# PIC32CX5112MTSH128 device description
Architecture: CORTEX-M4; Family: PIC32CXMT; Series: PIC32CXMTSH
Registers are 32-bit, read-write, no defined reset value unless marked. A register's access mark holds for its fields unless they carry their own. Offsets are from the block's base; [hi:lo] are bit positions.

## SFRBU — Special Function Register Backup
Instances: SFRBU 0x40050600
0x10 SFRBU_XTAL_TRIM — XTAL Oscillator Trimming Register
  [1:0] XTAL_TRIM — 32 kHz Crystal Oscillator Trimming Value
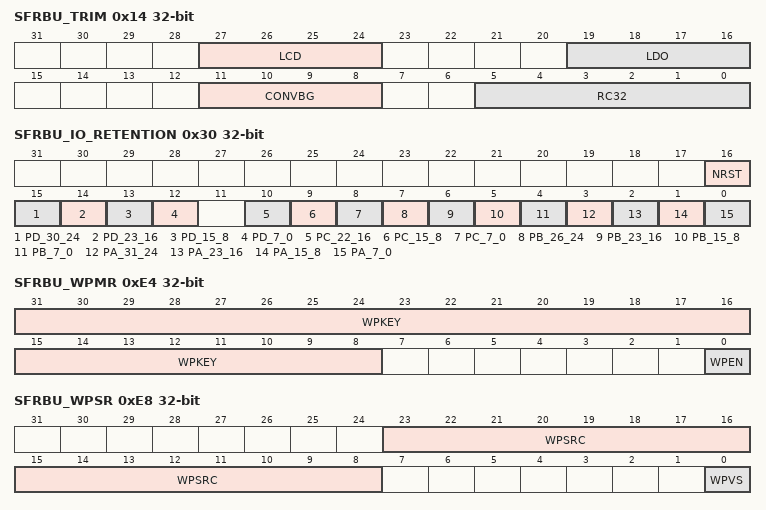
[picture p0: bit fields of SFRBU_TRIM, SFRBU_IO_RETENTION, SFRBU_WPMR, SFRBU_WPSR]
0x14 SFRBU_TRIM ro — Trimming Bits Register
  [27:24] LCD — LDO Internal Bandgap Trimming for LCD Driver
  [19:16] LDO — Power Management IP LDO Trimming Value
  [11:8] CONVBG — Conversion IP Bandgap Trimming Value
  [5:0] RC32 — RC Oscillator Trimming Value
0x20 SFRBU_BOOT — Boot Register
  [0] SOURCE — Source for Booting Sequence
0x30 SFRBU_IO_RETENTION — IO Retention Register
  [16] NRST — Keep Function on NRST
  [15] PD_30_24 — Keep Function on PD24 to PD30
  [14] PD_23_16 — Keep Function on PD16 to PD23
  [13] PD_15_8 — Keep Function on PD8 to PD15
  [12] PD_7_0 — Keep Function on PD0 to PD7
  [10] PC_22_16 — Keep Function on PC16 to PC22
  [9] PC_15_8 — Keep Function on PC8 to PC15
  [8] PC_7_0 — Keep Function on PC0 to PC7
  [7] PB_26_24 — Keep Function on PB24 to PB26
  [6] PB_23_16 — Keep Function on PB216 to PB23
  [5] PB_15_8 — Keep Function on PB8 to PB15
  [4] PB_7_0 — Keep Function on PB0 to PB7
  [3] PA_31_24 — Keep Function on PA24 to PA31
  [2] PA_23_16 — Keep Function on PA16 to PA23
  [1] PA_15_8 — Keep Function on PA8 to PA15
  [0] PA_7_0 — Keep Function on PA0 to PA7
0x40 SFRBU_BODCORE — BOD Core Register
  [0] STATUS — Core Brownout Detector
0x50 SFRBU_PWS_CNTRL — Power Switch Control Register
  [0] UNMASK — Unmask Power Switch Control Signals
0xE4 SFRBU_WPMR — Write Protection Mode Register
  [31:8] WPKEY — Write Protection Key
    0x534652=PASSWD (Writing any other value in this field aborts the write operation of the WPEN bit. Always reads as 0.)
  [0] WPEN — Write Protection Enable
0xE8 SFRBU_WPSR — Write Protection Status Register
  [23:8] WPSRC — Write Protection Source
  [0] WPVS — Write Protection Violation Status
0xF0 SFRBU_SPARE — Spare Register
  [31:0] VALUE — Spare

## SYSCWP — External Interrupt Controller
Instances: SYSCWP 0x400531A0
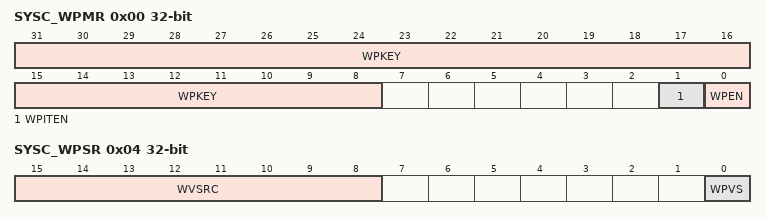
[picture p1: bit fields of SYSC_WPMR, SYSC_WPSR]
0x00 SYSC_WPMR — Write Protection Mode Register
  [31:8] WPKEY — Write Protection Key
    0x535943=PASSWD (Writing any other value in this field aborts the write operation of the WPEN and WPITEN bits. Always reads as 0.)
  [1] WPITEN — Write Protection Interrupt Enable
  [0] WPEN — Write Protection Enable
0x04 SYSC_WPSR ro — Write Protection Status Register
  [15:8] WVSRC — Write Violation Source
  [0] WPVS — Write Protection Register Violation Status

## TRNG — True Random Number Generator
Instances: TRNG 0x4400C000
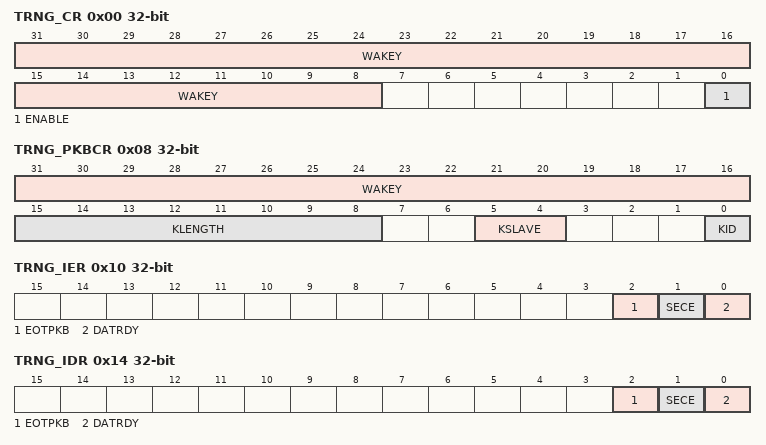
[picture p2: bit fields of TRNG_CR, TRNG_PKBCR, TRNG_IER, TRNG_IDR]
0x00 TRNG_CR wo — Control Register
  [31:8] WAKEY — Register Write Access Key
    0x524E47=PASSWD (Writing any other value in this field aborts the write operation.)
  [0] ENABLE — Enable TRNG to Provide Random Values
0x04 TRNG_MR — Mode Register
  [0] HALFR — Half Rate Enable
    0=DISABLED (Maximum stream rate provided (1 sample every 84 MCK clock cycles).); 1=ENABLED (Half maximum stream rate provided if the peripheral clock frequency is above 100 MHz (1 sample every 168 MCK clock cycles).)
0x08 TRNG_PKBCR wo — Private Key Bus Control Register
  [31:16] WAKEY — Register Write Access Key
    0x524B=PASSWD (Writing any other value in this field aborts the write operation.)
  [15:8] KLENGTH — Key Length
  [5:4] KSLAVE — Key Bus Client
    0=AES_ID; 1=AESB_ID
  [0] KID — Key ID (Must be Always Written to 0)
0x10 TRNG_IER wo — Interrupt Enable Register
  [2] EOTPKB — End Of Transfer on Private Key Bus Interrupt Enable
  [1] SECE — Security and/or Safety Event Interrupt Enable
  [0] DATRDY — Data Ready Interrupt Enable
0x14 TRNG_IDR wo — Interrupt Disable Register
  [2] EOTPKB — End Of Transfer on Private Key Bus Interrupt Disable
  [1] SECE — Security and/or Safety Event Interrupt Disable
  [0] DATRDY — Data Ready Interrupt Disable
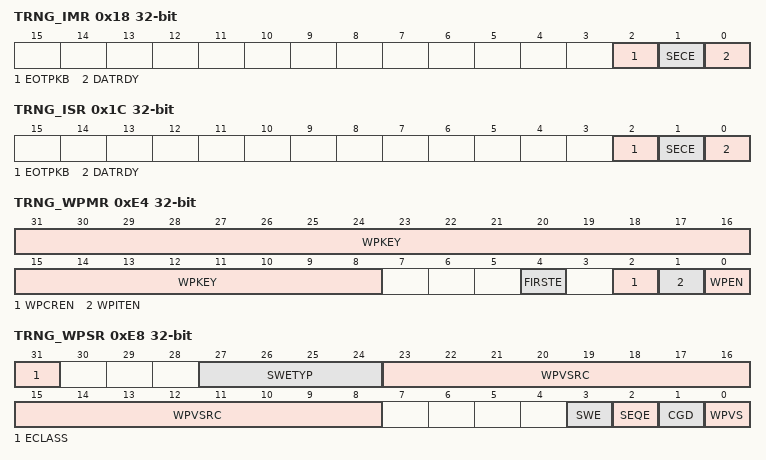
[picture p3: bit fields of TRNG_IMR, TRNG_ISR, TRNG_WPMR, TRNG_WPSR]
0x18 TRNG_IMR ro — Interrupt Mask Register
  [2] EOTPKB — End Of Transfer on Private Key Bus Interrupt Mask
  [1] SECE — Security and/or Safety Event Interrupt Mask
  [0] DATRDY — Data Ready Interrupt Mask
0x1C TRNG_ISR ro — Interrupt Status Register
  [2] EOTPKB — End Of Transfer on Private Key Bus (cleared on read)
  [1] SECE — Security and/or Safety Event (cleared on read)
  [0] DATRDY — Data Ready (cleared on read)
0x50 TRNG_ODATA ro — Output Data Register
  [31:0] ODATA — Output Data
0xE4 TRNG_WPMR — Write Protection Mode Register
  [31:8] WPKEY — Write Protection Key
    0x524E47=PASSWD (Writing any other value in this field aborts the write operation of bits WPEN, WPITEN and WPCREN. Always reads as 0.)
  [4] FIRSTE — First Error Report Enable
  [2] WPCREN — Write Protection Control Enable
  [1] WPITEN — Write Protection Interrupt Enable
  [0] WPEN — Write Protection Enable
0xE8 TRNG_WPSR ro — Write Protection Status Register
  [31] ECLASS — Software Error Class (cleared on read)
    0=WARNING (An abnormal access that does not affect system functionality.); 1=ERROR (Reading TRNG_ODATA when TRNG was disabled or TRNG used for private key bus transfer. TRNG does not provide a random value. Writing to TRNG_PKBCR while a private key bus transfer is ongoing does not launch a new private key bus transfer.)
  [27:24] SWETYP — Software Error Type (cleared on read)
    0=READ_WO (TRNG is enabled and a write-only register has been read (Warning).); 1=WRITE_RO (TRNG is enabled and a write access has been performed on a read-only register (Warning).); 2=UNDEF_RW (Access to an undefined address.); 3=TRNG_DIS (The TRNG_ODATA register was read when TRNG was disabled or TRNG used for private key bus transfer (Error).); 4=PKB_BUSY (A write access to TRNG_PKBCR has been attempted during a private key bus transfer (Error).)
  [23:8] WPVSRC — Write Protection Violation Source (cleared on read)
  [3] SWE — Software Control Error (cleared on read)
  [2] SEQE — Internal Sequencer Error (cleared on read)
  [1] CGD — Clock Glitch Detected (cleared on read)
  [0] WPVS — Write Protection Violation Status (cleared on read)

## Notices in the file
Copyright %copyright_year% Microchip Technology Inc.
SPDX-License-Identifier: Apache-2.0
Licensed under the Apache License, Version 2.0 (the "License");
you may not use this file except in compliance with the License.
You may obtain a copy of the License at
http://www.apache.org/licenses/LICENSE-2.0
Unless required by applicable law or agreed to in writing, software
distributed under the License is distributed on an "AS IS" BASIS,
WITHOUT WARRANTIES OR CONDITIONS OF ANY KIND, either express or implied.
See the License for the specific language governing permissions and
limitations under the License.
